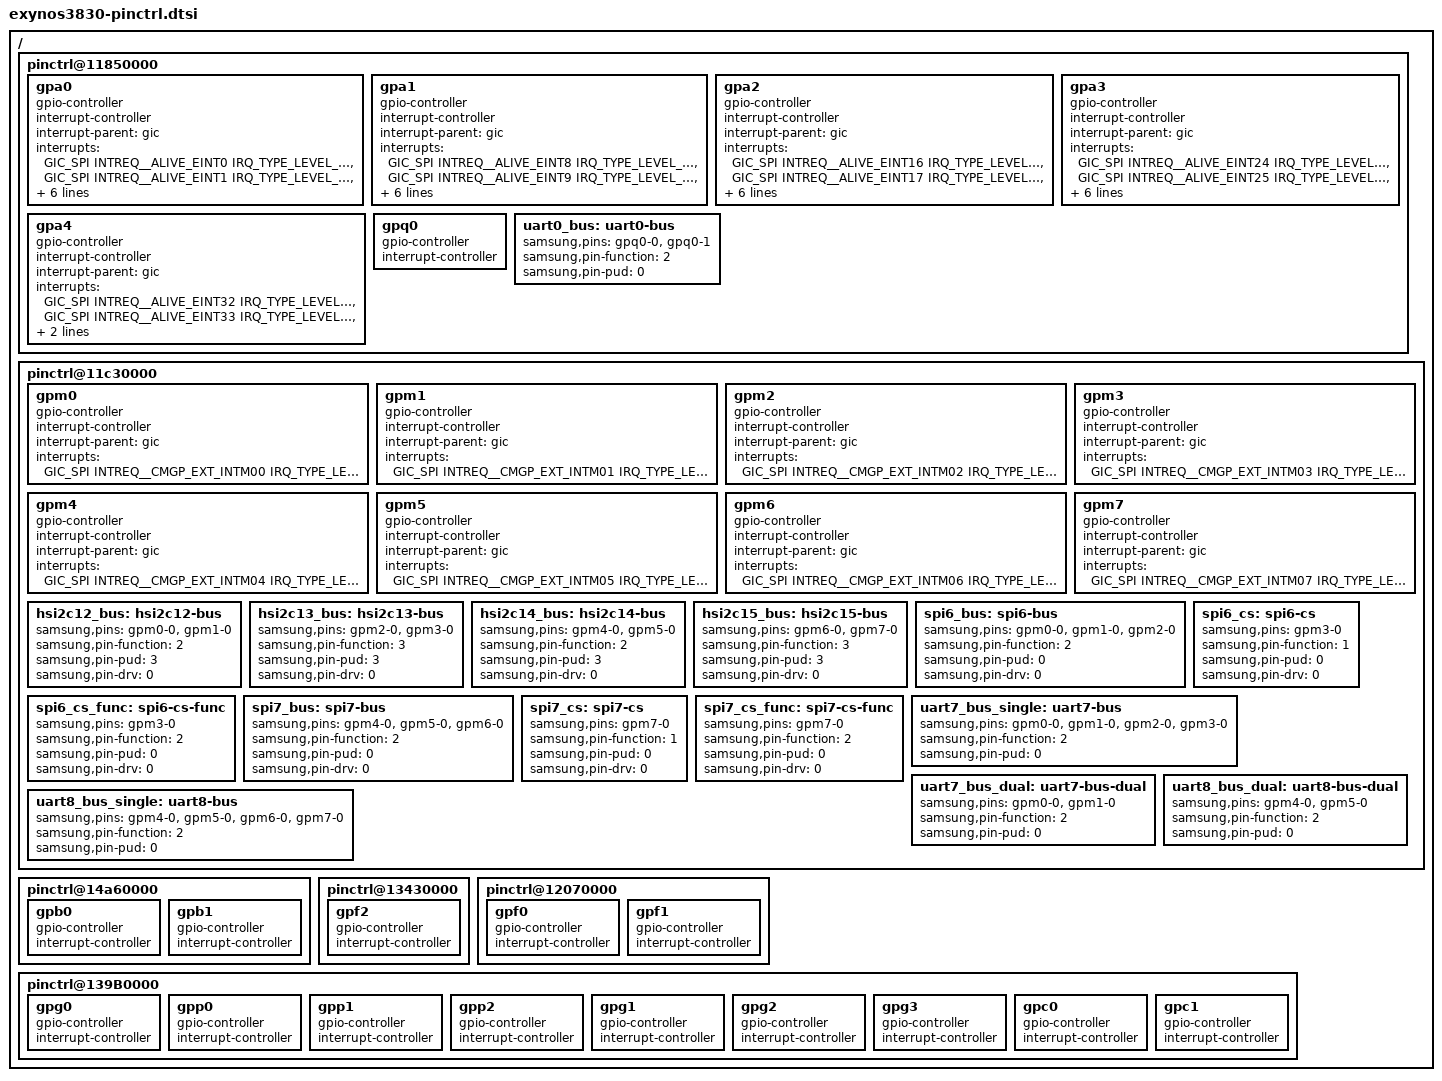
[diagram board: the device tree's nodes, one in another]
/*
 * Samsung's Exynos3830 SoC pin-mux and pin-config device tree source
 *
 * Copyright (c) 2017 Samsung Electronics Co., Ltd.
 *		http://www.samsung.com
 *
 * Samsung's Exynos3830 SoC pin-mux and pin-config options are listed as device
 * tree nodes are listed in this file.
 *
 * This program is free software; you can redistribute it and/or modify
 * it under the terms of the GNU General Public License version 2 as
 * published by the Free Software Foundation.
*/

/ {
	/* ALIVE */
	pinctrl@11850000 {
		gpa0: gpa0 {
			gpio-controller;
			#gpio-cells = <2>;

			interrupt-controller;
			#interrupt-cells = <3>;
			interrupt-parent = <&gic>;
			interrupts = <GIC_SPI INTREQ__ALIVE_EINT0 IRQ_TYPE_LEVEL_HIGH>,
				     <GIC_SPI INTREQ__ALIVE_EINT1 IRQ_TYPE_LEVEL_HIGH>,
				     <GIC_SPI INTREQ__ALIVE_EINT2 IRQ_TYPE_LEVEL_HIGH>,
				     <GIC_SPI INTREQ__ALIVE_EINT3 IRQ_TYPE_LEVEL_HIGH>,
				     <GIC_SPI INTREQ__ALIVE_EINT4 IRQ_TYPE_LEVEL_HIGH>,
				     <GIC_SPI INTREQ__ALIVE_EINT5 IRQ_TYPE_LEVEL_HIGH>,
				     <GIC_SPI INTREQ__ALIVE_EINT6 IRQ_TYPE_LEVEL_HIGH>,
				     <GIC_SPI INTREQ__ALIVE_EINT7 IRQ_TYPE_LEVEL_HIGH>;
		};

		gpa1: gpa1 {
			gpio-controller;
			#gpio-cells = <2>;

			interrupt-controller;
			#interrupt-cells = <3>;
			interrupt-parent = <&gic>;
			interrupts = <GIC_SPI INTREQ__ALIVE_EINT8 IRQ_TYPE_LEVEL_HIGH>,
				     <GIC_SPI INTREQ__ALIVE_EINT9 IRQ_TYPE_LEVEL_HIGH>,
				     <GIC_SPI INTREQ__ALIVE_EINT10 IRQ_TYPE_LEVEL_HIGH>,
				     <GIC_SPI INTREQ__ALIVE_EINT11 IRQ_TYPE_LEVEL_HIGH>,
				     <GIC_SPI INTREQ__ALIVE_EINT12 IRQ_TYPE_LEVEL_HIGH>,
				     <GIC_SPI INTREQ__ALIVE_EINT13 IRQ_TYPE_LEVEL_HIGH>,
				     <GIC_SPI INTREQ__ALIVE_EINT14 IRQ_TYPE_LEVEL_HIGH>,
				     <GIC_SPI INTREQ__ALIVE_EINT15 IRQ_TYPE_LEVEL_HIGH>;
		};

		gpa2: gpa2 {
			gpio-controller;
			#gpio-cells = <2>;

			interrupt-controller;
			#interrupt-cells = <3>;
			interrupt-parent = <&gic>;
			interrupts = <GIC_SPI INTREQ__ALIVE_EINT16 IRQ_TYPE_LEVEL_HIGH>,
				     <GIC_SPI INTREQ__ALIVE_EINT17 IRQ_TYPE_LEVEL_HIGH>,
				     <GIC_SPI INTREQ__ALIVE_EINT18 IRQ_TYPE_LEVEL_HIGH>,
				     <GIC_SPI INTREQ__ALIVE_EINT19 IRQ_TYPE_LEVEL_HIGH>,
				     <GIC_SPI INTREQ__ALIVE_EINT20 IRQ_TYPE_LEVEL_HIGH>,
				     <GIC_SPI INTREQ__ALIVE_EINT21 IRQ_TYPE_LEVEL_HIGH>,
				     <GIC_SPI INTREQ__ALIVE_EINT22 IRQ_TYPE_LEVEL_HIGH>,
				     <GIC_SPI INTREQ__ALIVE_EINT23 IRQ_TYPE_LEVEL_HIGH>;
		};

		gpa3: gpa3 {
			gpio-controller;
			#gpio-cells = <2>;

			interrupt-controller;
			#interrupt-cells = <3>;
			interrupt-parent = <&gic>;
			interrupts = <GIC_SPI INTREQ__ALIVE_EINT24 IRQ_TYPE_LEVEL_HIGH>,
				     <GIC_SPI INTREQ__ALIVE_EINT25 IRQ_TYPE_LEVEL_HIGH>,
				     <GIC_SPI INTREQ__ALIVE_EINT26 IRQ_TYPE_LEVEL_HIGH>,
				     <GIC_SPI INTREQ__ALIVE_EINT27 IRQ_TYPE_LEVEL_HIGH>,
				     <GIC_SPI INTREQ__ALIVE_EINT28 IRQ_TYPE_LEVEL_HIGH>,
				     <GIC_SPI INTREQ__ALIVE_EINT29 IRQ_TYPE_LEVEL_HIGH>,
				     <GIC_SPI INTREQ__ALIVE_EINT30 IRQ_TYPE_LEVEL_HIGH>,
				     <GIC_SPI INTREQ__ALIVE_EINT31 IRQ_TYPE_LEVEL_HIGH>;
		};

		gpa4: gpa4 {
			gpio-controller;
			#gpio-cells = <2>;

			interrupt-controller;
			#interrupt-cells = <3>;
			interrupt-parent = <&gic>;
			interrupts = <GIC_SPI INTREQ__ALIVE_EINT32 IRQ_TYPE_LEVEL_HIGH>,
				     <GIC_SPI INTREQ__ALIVE_EINT33 IRQ_TYPE_LEVEL_HIGH>,
				     <GIC_SPI INTREQ__ALIVE_EINT34 IRQ_TYPE_LEVEL_HIGH>,
				     <GIC_SPI INTREQ__ALIVE_EINT35 IRQ_TYPE_LEVEL_HIGH>;
		};

		gpq0: gpq0 {
			gpio-controller;
			#gpio-cells = <2>;

			interrupt-controller;
			#interrupt-cells = <2>;
		};

		/* USI_PERI_UART_DBG */
		uart0_bus: uart0-bus {
			samsung,pins = "gpq0-0", "gpq0-1";
			samsung,pin-function = <2>;
			samsung,pin-pud = <0>;
		};
	};

	/* CMGP */
	pinctrl@11c30000 {
		gpm0: gpm0 {
			gpio-controller;
			#gpio-cells = <2>;

			interrupt-controller;
			#interrupt-cells = <3>;
			interrupt-parent = <&gic>;
			interrupts = <GIC_SPI INTREQ__CMGP_EXT_INTM00 IRQ_TYPE_LEVEL_HIGH>;
		};

		gpm1: gpm1 {
			gpio-controller;
			#gpio-cells = <2>;

			interrupt-controller;
			#interrupt-cells = <3>;
			interrupt-parent = <&gic>;
			interrupts = <GIC_SPI INTREQ__CMGP_EXT_INTM01 IRQ_TYPE_LEVEL_HIGH>;
		};

		gpm2: gpm2 {
			gpio-controller;
			#gpio-cells = <2>;

			interrupt-controller;
			#interrupt-cells = <3>;
			interrupt-parent = <&gic>;
			interrupts = <GIC_SPI INTREQ__CMGP_EXT_INTM02 IRQ_TYPE_LEVEL_HIGH>;
		};

		gpm3: gpm3 {
			gpio-controller;
			#gpio-cells = <2>;

			interrupt-controller;
			#interrupt-cells = <3>;
			interrupt-parent = <&gic>;
			interrupts = <GIC_SPI INTREQ__CMGP_EXT_INTM03 IRQ_TYPE_LEVEL_HIGH>;
		};

		gpm4: gpm4 {
			gpio-controller;
			#gpio-cells = <2>;

			interrupt-controller;
			#interrupt-cells = <3>;
			interrupt-parent = <&gic>;
			interrupts = <GIC_SPI INTREQ__CMGP_EXT_INTM04 IRQ_TYPE_LEVEL_HIGH>;
		};

		gpm5: gpm5 {
			gpio-controller;
			#gpio-cells = <2>;

			interrupt-controller;
			#interrupt-cells = <3>;
			interrupt-parent = <&gic>;
			interrupts = <GIC_SPI INTREQ__CMGP_EXT_INTM05 IRQ_TYPE_LEVEL_HIGH>;
		};
		gpm6: gpm6 {
			gpio-controller;
			#gpio-cells = <2>;

			interrupt-controller;
			#interrupt-cells = <3>;
			interrupt-parent = <&gic>;
			interrupts = <GIC_SPI INTREQ__CMGP_EXT_INTM06 IRQ_TYPE_LEVEL_HIGH>;
		};

		gpm7: gpm7 {
			gpio-controller;
			#gpio-cells = <2>;

			interrupt-controller;
			#interrupt-cells = <3>;
			interrupt-parent = <&gic>;
			interrupts = <GIC_SPI INTREQ__CMGP_EXT_INTM07 IRQ_TYPE_LEVEL_HIGH>;
		};

		/* usi_cmgp00 */
		hsi2c12_bus: hsi2c12-bus {
			samsung,pins = "gpm0-0", "gpm1-0";
			samsung,pin-function = <2>;
			samsung,pin-pud = <3>;
			samsung,pin-drv = <0>;
		};

		/* usi_cmgp00_i2c */
		hsi2c13_bus: hsi2c13-bus {
			samsung,pins = "gpm2-0", "gpm3-0";
			samsung,pin-function = <3>;
			samsung,pin-pud = <3>;
			samsung,pin-drv = <0>;
		};

		/* usi_cmgp01 */
		hsi2c14_bus: hsi2c14-bus {
			samsung,pins = "gpm4-0", "gpm5-0";
			samsung,pin-function = <2>;
			samsung,pin-pud = <3>;
			samsung,pin-drv = <0>;
		};

		/* usi_cmgp01_i2c */
		hsi2c15_bus: hsi2c15-bus {
			samsung,pins = "gpm6-0", "gpm7-0";
			samsung,pin-function = <3>;
			samsung,pin-pud = <3>;
			samsung,pin-drv = <0>;
		};
		/* spi usi_cmgp00 */
		spi6_bus: spi6-bus {
				samsung,pins = "gpm0-0", "gpm1-0", "gpm2-0";
				samsung,pin-function = <2>;
				samsung,pin-pud = <0>;
				samsung,pin-drv = <0>;
		};

		spi6_cs: spi6-cs {
				samsung,pins = "gpm3-0";
				samsung,pin-function = <1>;
				samsung,pin-pud = <0>;
				samsung,pin-drv = <0>;
		};

		spi6_cs_func: spi6-cs-func {
				samsung,pins = "gpm3-0";
				samsung,pin-function = <2>;
				samsung,pin-pud = <0>;
				samsung,pin-drv = <0>;
		};

		/* spi usi_cmgp01 */
		spi7_bus: spi7-bus {
				samsung,pins = "gpm4-0", "gpm5-0", "gpm6-0";
				samsung,pin-function = <2>;
				samsung,pin-pud = <0>;
				samsung,pin-drv = <0>;
		};

		spi7_cs: spi7-cs {
				samsung,pins = "gpm7-0";
				samsung,pin-function = <1>;
				samsung,pin-pud = <0>;
				samsung,pin-drv = <0>;
		};

		spi7_cs_func: spi7-cs-func {
				samsung,pins = "gpm7-0";
				samsung,pin-function = <2>;
				samsung,pin-pud = <0>;
				samsung,pin-drv = <0>;
		};

		/* usi_cmgp00_uart */
		uart7_bus_single: uart7-bus {
				samsung,pins = "gpm0-0", "gpm1-0", "gpm2-0", "gpm3-0";
				samsung,pin-function = <2>;
				samsung,pin-pud = <0>;
		};

		uart7_bus_dual: uart7-bus-dual {
				samsung,pins = "gpm0-0", "gpm1-0";
				samsung,pin-function = <2>;
				samsung,pin-pud = <0>;
		};

		/* usi_cmgp01_uart */
		uart8_bus_single: uart8-bus {
				samsung,pins = "gpm4-0", "gpm5-0", "gpm6-0", "gpm7-0";
				samsung,pin-function = <2>;
				samsung,pin-pud = <0>;
		};

		uart8_bus_dual: uart8-bus-dual {
				samsung,pins = "gpm4-0", "gpm5-0";
				samsung,pin-function = <2>;
				samsung,pin-pud = <0>;
		};
	};

	/* AUD */
	pinctrl@14a60000{
		gpb0: gpb0 {
			gpio-controller;
			#gpio-cells = <2>;

			interrupt-controller;
			#interrupt-cells = <2>;
		};

		gpb1: gpb1 {
			gpio-controller;
			#gpio-cells = <2>;

			interrupt-controller;
			#interrupt-cells = <2>;
		};
	};

	/* HSI */
	pinctrl@13430000 {
		gpf2: gpf2 {
			gpio-controller;
			#gpio-cells = <2>;

			interrupt-controller;
			#interrupt-cells = <2>;
		};
	};

	/* CORE */
	pinctrl@12070000 {
		gpf0: gpf0 {
			gpio-controller;
			#gpio-cells = <2>;

			interrupt-controller;
			#interrupt-cells = <2>;
		};

		gpf1: gpf1 {
			gpio-controller;
			#gpio-cells = <2>;

			interrupt-controller;
			#interrupt-cells = <2>;
		};
	};

	/* PERI */
	pinctrl@139B0000 {
		gpg0: gpg0 {
			gpio-controller;
			#gpio-cells = <2>;

			interrupt-controller;
			#interrupt-cells = <2>;
		};

		gpp0: gpp0 {
			gpio-controller;
			#gpio-cells = <2>;

			interrupt-controller;
			#interrupt-cells = <2>;
		};
		gpp1: gpp1 {
			gpio-controller;
			#gpio-cells = <2>;

			interrupt-controller;
			#interrupt-cells = <2>;
		};

		gpp2: gpp2 {
			gpio-controller;
			#gpio-cells = <2>;

			interrupt-controller;
			#interrupt-cells = <2>;
		};

		gpg1: gpg1 {
			gpio-controller;
			#gpio-cells = <2>;

			interrupt-controller;
			#interrupt-cells = <2>;
		};

		gpg2: gpg2 {
			gpio-controller;
			#gpio-cells = <2>;

			interrupt-controller;
			#interrupt-cells = <2>;
		};

		gpg3: gpg3 {
			gpio-controller;
			#gpio-cells = <2>;

			interrupt-controller;
			#interrupt-cells = <2>;
		};

		gpc0: gpc0 {
			gpio-controller;
			#gpio-cells = <2>;

			interrupt-controller;
			#interrupt-cells = <2>;
		};

		gpc1: gpc1 {
			gpio-controller;
			#gpio-cells = <2>;

			interrupt-controller;
			#interrupt-cells = <2>;
		};
	};
};
